# wiz16b8m4ct3_0_WIZ16B8M4CT3 register map
Vendor: Texas Instruments
Registers are 32-bit, read-write, reset 0x0 unless marked. A register's access mark holds for its fields unless they carry their own. Offsets are as the file gives them; [hi:lo] are bit positions; {n}, {i} and the like mark numbered series.

## wiz16b8m4ct3_0_WIZ16B8M4CT3 (part 3 of 12)
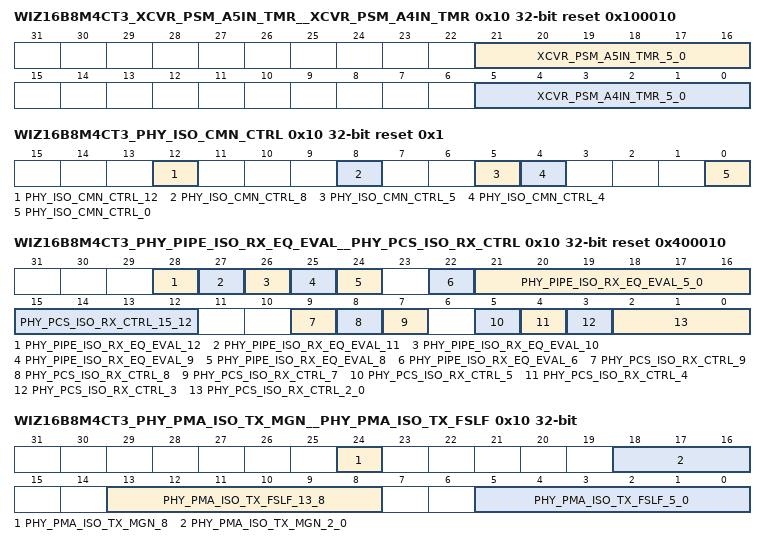
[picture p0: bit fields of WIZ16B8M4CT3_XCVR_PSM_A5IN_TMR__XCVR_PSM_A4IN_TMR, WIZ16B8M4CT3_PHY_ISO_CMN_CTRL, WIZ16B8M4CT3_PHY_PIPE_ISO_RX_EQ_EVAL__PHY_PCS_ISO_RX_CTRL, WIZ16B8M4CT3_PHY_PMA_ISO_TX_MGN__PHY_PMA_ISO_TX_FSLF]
0x10 WIZ16B8M4CT3_XCVR_PSM_A5IN_TMR__XCVR_PSM_A4IN_TMR reset 0x100010
  [21:16] XCVR_PSM_A5IN_TMR_5_0 — A5 in delay state timer value : Value used for the timer when the power state machine is in the A5 in delay state. This timer delay is specified as the number of PSM clocks to count to implement the time required for tpsm_A5_in_del. Note, the smallest value this field is allowed to be is 6'h01. With that said, setting this field to a value smaller than the reset value will likely result in incorrect function.
  [5:0] XCVR_PSM_A4IN_TMR_5_0 — A4 in delay state timer value : Value used for the timer when the power state machine is in the A4 in delay state. This timer delay is specified as the number of PSM clocks to count to implement the time required for tpsm_A4_in_del. Note, the smallest value this field is allowed to be is 6'h01. With that said, setting this field to a value smaller than the reset value will likely result in incorrect function.
0x10 WIZ16B8M4CT3_PHY_ISO_CMN_CTRL access per field reset 0x1
  [12] PHY_ISO_CMN_CTRL_12 ro — Current value of phy_refclk_reqd PHY output.
  [8] PHY_ISO_CMN_CTRL_8 rw — Drives phy_en_refclk PHY input when in PHY macro and PMA isolation mode.
  [5] PHY_ISO_CMN_CTRL_5 rw — Drives phy_pma_suspend_override PHY input when in PHY macro and PMA isolation mode.
  [4] PHY_ISO_CMN_CTRL_4 rw — Drives refclk_rcvr_pwrdn internal PHY signal when in PHY macro and PMA isolation mode (1 = powers down the reference clock receiver). During normal operation, refclk_rcvr_pwrdn is driven from ~abp_preset_n, which powers down the reference clock receiver when the PHY is disabled.
  [0] PHY_ISO_CMN_CTRL_0 rw — Drives phy_reset_n PHY input when in PHY macro and PMA isolation mode.
0x10 WIZ16B8M4CT3_PHY_PIPE_ISO_RX_EQ_EVAL__PHY_PCS_ISO_RX_CTRL access per field reset 0x400010
  [28] PHY_PIPE_ISO_RX_EQ_EVAL_12 rw — Drives pipe_invalid_request for the associated lane when in PHY macro and PMA isolation modes.
  [27] PHY_PIPE_ISO_RX_EQ_EVAL_11 rw — pipe_link_eval_dir_change[5:4] bit reversal enable. When low, no bit reversal. When high, the bit positions for pipe_link_eval_dir_change[5:4] PHY output for the associated lane are reversed.
  [26] PHY_PIPE_ISO_RX_EQ_EVAL_10 rw — pipe_link_eval_dir_change[3:2] bit reversal enable. When low, no bit reversal. When high, the bit positions for pipe_link_eval_dir_change[3:2] PHY output for the associated lane are reversed.
  [25] PHY_PIPE_ISO_RX_EQ_EVAL_9 rw — pipe_link_eval_dir_change[1:0] bit reversal enable. When low, no bit reversal. When high, the bit positions for pipe_link_eval_dir_change[1:0] PHY output for the associated lane are reversed.]
  [24] PHY_PIPE_ISO_RX_EQ_EVAL_8 rw — Drives pipe_rx_eval PHY input for the associated lane when in PHY macro and PMA isolation modes.
  [22] PHY_PIPE_ISO_RX_EQ_EVAL_6 ro — Captures pipe_phy_status for Rx equalization evaluation PHY output for the associated lane (does not include power state change signaling). Set when pipe_phy_status is high and pipe_rx_eq_eval to the PCS is high (i.e. after the isolation MUX). Cleared upon read.
  [21:16] PHY_PIPE_ISO_RX_EQ_EVAL_5_0 ro — pipe_link_eval_dir_change PHY output for the associated lane (prior to bit reversal logic) upon completion of Rx equalization evaluation. Captured upon assertion of Rx equalization eval pipe_phy_status when pipe_rx_eq_eval to the PCS (i.e. after the isolation MUX) is high. Cleared upon read. (Not re-synchronized to apb_pclk)
  [15:12] PHY_PCS_ISO_RX_CTRL_15_12 ro — Current value of pipe_rx_data_k PHY output for the associated lane, when PHY_PCS_ISO_RX_CTRL[5] == 1. Otherwise, 0. (Not re-synchronized to apb_pclk)
  [9] PHY_PCS_ISO_RX_CTRL_9 rw — Drives pipe_rx_eq_training PHY input for the associated lane when in PHY macro and PMA isolation modes.
  [8] PHY_PCS_ISO_RX_CTRL_8 rw — Drives pipe_rx_termination PHY input for the associated lane when in PHY macro and PMA isolation modes.
  [7] PHY_PCS_ISO_RX_CTRL_7 rw — Drives pipe_rx_polarity PHY input for the associated lane when in PHY macro and PMA isolation modes.
  [5] PHY_PCS_ISO_RX_CTRL_5 ro — Current value of pipe_rx_valid PHY output for the associated lane.
  [4] PHY_PCS_ISO_RX_CTRL_4 ro — Current value of pipe_rx_elec_idle PHY output for the associated lane.
  [3] PHY_PCS_ISO_RX_CTRL_3 ro — Current value of pipe_align_detect PHY output for the associated lane.
  [2:0] PHY_PCS_ISO_RX_CTRL_2_0 ro — Current value of pipe_rx_status PHY output for the associated lane. Holds the highest priority pipe_rx_status value seen, since the last register read. Cleared upon read.
0x10 WIZ16B8M4CT3_PHY_PMA_ISO_TX_MGN__PHY_PMA_ISO_TX_FSLF access per field
  [24] PHY_PMA_ISO_TX_MGN_8 rw — Drives tx_low_power_swing_en PMA input for the associated lane when in PMA isolation mode or PHY isolation mode and lane is configured for Raw SerDes mode.
  [18:16] PHY_PMA_ISO_TX_MGN_2_0 rw — Drives tx_vmargin PMA input for the associated lane when in PMA isolation mode or PHY isolation mode and lane is configured for Raw SerDes mode.
  [13:8] PHY_PMA_ISO_TX_FSLF_13_8 ro — Current value of tx_local_fs PMA ouptut for the associated lane. (Not re-synchronized to apb_pclk) Note: In a RTL simulation without UPF, the reset value of this field will be 0x2D.
  [5:0] PHY_PMA_ISO_TX_FSLF_5_0 ro — Current value of tx_local_lf PMA ouptut for the associated lane. (Not re-synchronized to apb_pclk) Note: In a RTL simulation without UPF, the reset value of this field will be 0x0F.
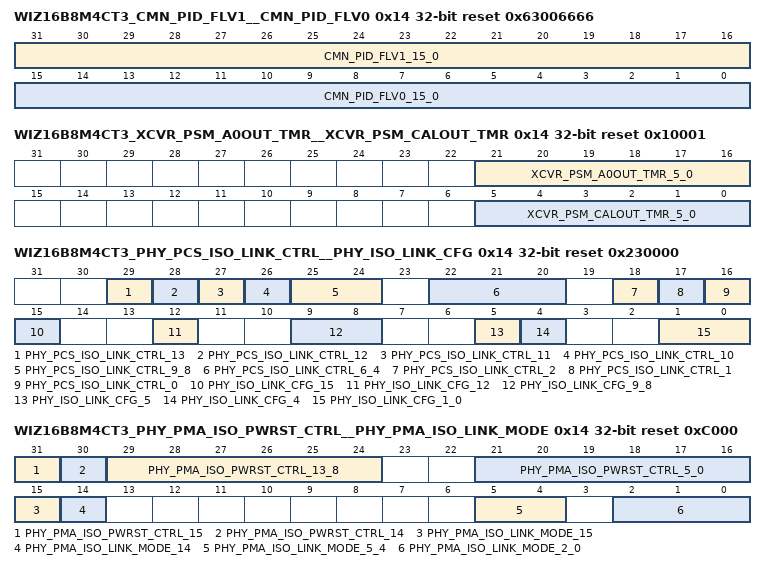
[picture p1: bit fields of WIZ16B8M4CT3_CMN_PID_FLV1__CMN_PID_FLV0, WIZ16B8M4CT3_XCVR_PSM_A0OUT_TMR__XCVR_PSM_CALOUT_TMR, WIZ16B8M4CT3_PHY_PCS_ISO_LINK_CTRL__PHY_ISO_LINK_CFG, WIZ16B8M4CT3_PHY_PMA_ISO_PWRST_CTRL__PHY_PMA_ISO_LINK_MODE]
0x14 WIZ16B8M4CT3_CMN_PID_FLV1__CMN_PID_FLV0 ro reset 0x63006666
  [31:16] CMN_PID_FLV1_15_0 — Product technology flavor : This field contains the ASCII codes that represent the second two characters of the product technology flavor. c
  [15:0] CMN_PID_FLV0_15_0 — Product technology flavor : This field contains the ASCII codes that represent the first two characters of the product technology flavor.
0x14 WIZ16B8M4CT3_XCVR_PSM_A0OUT_TMR__XCVR_PSM_CALOUT_TMR reset 0x10001
  [21:16] XCVR_PSM_A0OUT_TMR_5_0 — A0 out delay state timer value : Value used for the timer when the power state machine is in the A0 out delay state. This timer delay is specified as the number of PSM clocks to count to implement the time required for tpsm_A0_out_del. Note, the smallest value this field is allowed to be is 6'h01. With that said, setting this field to a value smaller than the reset value will likely result in incorrect function.
  [5:0] XCVR_PSM_CALOUT_TMR_5_0 — PSM calibration out delay state timer value : Value used for the timer when the power state machine is in the PSM calibration out delay state. This timer delay is specified as the number of PSM clocks to count to implement the time required for tpsm_lane_cal_out_del. Note, the smallest value this field is allowed to be is 6'h01. With that said, setting this field to a value smaller than the reset value will likely result in incorrect function.
0x14 WIZ16B8M4CT3_PHY_STATE_CHG_TIMEOUT reset 0x30D4
  [15:0] PHY_STATE_CHG_TIMEOUT_15_0 — State change timeout: Bits [19:4] of the state change timeout (bits [3:0] are zero). The timeout is the maximum number of APB clock cycles (abp_pclk) that are allowed for completion of a PHY power state change for the link. If the timeout expires, phy_interrupt_ln_XX for the associated lane is asserted and interrupt status register bit is set. For maximum allowed APB clock frequency, this provides 5.2 msec maximum timeout. Default is set for 1 msec for the maximum APB clock frequency.
0x14 WIZ16B8M4CT3_PHY_PCS_ISO_LINK_CTRL__PHY_ISO_LINK_CFG access per field reset 0x230000
  [29] PHY_PCS_ISO_LINK_CTRL_13 ro — Current value of phy_l*_ack_l1_x PHY output for the associated lane. ()
  [28] PHY_PCS_ISO_LINK_CTRL_12 rw — Drives the phy_l*_ent_l1_x PHY input for the associated lane when in PHY macro and PMA isolation modes. (Link signal - for multi-lane links, master lane used for all lanes in link.)
  [27] PHY_PCS_ISO_LINK_CTRL_11 rw — Drives the phy_l*_rx_elec_idle_det_en PHY input for the associated lane when in PHY macro and PMA isolation modes. (Link signal - for multi-lane links, master lane used for all lanes in link.)
  [26] PHY_PCS_ISO_LINK_CTRL_10 rw — Drives the phy_l*_tx_cmn_mode_en PHY input for the associated lane when in PHY macro and PMA isolation modes. (Link signal - for multi-lane links, master lane used for all lanes in link.)
  [25:24] PHY_PCS_ISO_LINK_CTRL_9_8 rw — Drives the pipe_l*_rate PHY input for the associated lane when in PHY macro and PMA isolation modes. (Link signal - for multi-lane links, master lane used for all lanes in link.)
  [22:20] PHY_PCS_ISO_LINK_CTRL_6_4 rw — Drives the pipe_l*_powerdown PHY input for the associated lane when in PHY macro and PMA isolation modes. (Link signal - for multi-lane links, master lane used for all lanes in link.)
  [18] PHY_PCS_ISO_LINK_CTRL_2 rw — Drives the pipe_l*_tx_det_rx_lpbk PHY input for the associated lane when in PHY macro and PMA isolation modes. (Link signal - for multi-lane links, master lane used for all lanes in link.)
  [17] PHY_PCS_ISO_LINK_CTRL_1 ro — Captures pipe_l*_phy_status (for power state and rate change) PHY output for the associated lane. Set when pipe_phy_status is high and cleared upon read if pipe_phy_status is low. ()
  [16] PHY_PCS_ISO_LINK_CTRL_0 rw — Drives the phy_l*_reset_n PHY input for the associated lane when in PHY macro and PMA isolation modes. (Link signal - for multi-lane links, master lane used for all lanes in link.)
  [15] PHY_ISO_LINK_CFG_15 rw — Drives phy_link_cfg_ln_{nnnn} PHY input when in PHY macro and PMA isolation modes.
  [12] PHY_ISO_LINK_CFG_12 rw — Drives pipe_l{nnnn}_32bit_sel PHY input when in PHY macro and PMA isolation modes.
  [9:8] PHY_ISO_LINK_CFG_9_8 rw — Drives pma_fullrt_div_ln_{nnnn} PHY input when in PHY macro and PMA isolation modes.
  [5] PHY_ISO_LINK_CFG_5 rw — Drives pipe_l{nnnn}_pcie_l1_ss_sel PHY input when in PHY macro and PMA isolation mode.
  [4] PHY_ISO_LINK_CFG_4 rw — Drives pipe_l{nnnn}_eb_mode PHY input when in PHY macro and PMA isolation modes.
  [1:0] PHY_ISO_LINK_CFG_1_0 rw — Drives phy_l{nnnn}_mode PHY input when in PHY macro and PMA isolation modes.
0x14 WIZ16B8M4CT3_PHY_PMA_PLL0_SM_STATE ro reset 0x3000000
  [27:16] PHY_PMA_PLL0_SM_STATE_11_0 — Current value of cmn_pllsm0_state[11:0]. PMA output (Debug only: Not re-synchronized)
0x14 WIZ16B8M4CT3_PHY_PMA_ISO_PWRST_CTRL__PHY_PMA_ISO_LINK_MODE access per field reset 0xC000
  [31] PHY_PMA_ISO_PWRST_CTRL_15 rw — rx_sig_det_en_ext_ln_{nnnn} PMA input when in PMA isolation mode. (Used for PCIe)
  [30] PHY_PMA_ISO_PWRST_CTRL_14 rw — tx_cmn_mode_en_ext_ln_{nnnn} PMA input when in PMA isolation mode. (Used for PCIe)
  [29:24] PHY_PMA_ISO_PWRST_CTRL_13_8 ro — Current value of xcvr_power_state_ack_ln_{nnnn} PMA output.
  [21:16] PHY_PMA_ISO_PWRST_CTRL_5_0 rw — Drives xcvr_power_state_req_ln_{nnnn} PMA input when in PMA isolation mode or PHY isolation mode and lane is configured for Raw SerDes mode..
  [15] PHY_PMA_ISO_LINK_MODE_15 rw — tx_reset_n_ln_{nnnn} PMA input when in PMA isolation mode.
  [14] PHY_PMA_ISO_LINK_MODE_14 rw — rx_reset_n_ln_{nnnn} PMA input when in PMA isolation mode.
  [5:4] PHY_PMA_ISO_LINK_MODE_5_4 rw — Drives xcvr_standard_mode_ln_{nnnn} PMA input when in PMA isolation mode or PHY isolation mode and lane is configured for Raw SerDes mode.
  [2:0] PHY_PMA_ISO_LINK_MODE_2_0 rw — Drives xcvr_data_width_ln_{nnnn} PMA input when in PMA isolation mode or PHY isolation mode and lane is configured for Raw SerDes mode.
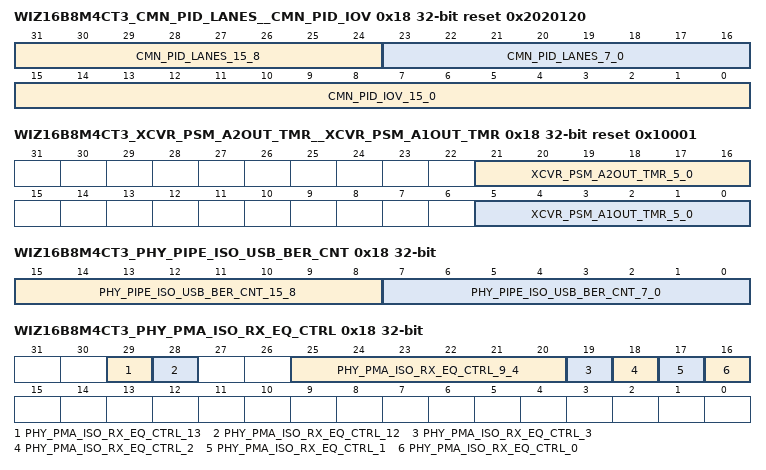
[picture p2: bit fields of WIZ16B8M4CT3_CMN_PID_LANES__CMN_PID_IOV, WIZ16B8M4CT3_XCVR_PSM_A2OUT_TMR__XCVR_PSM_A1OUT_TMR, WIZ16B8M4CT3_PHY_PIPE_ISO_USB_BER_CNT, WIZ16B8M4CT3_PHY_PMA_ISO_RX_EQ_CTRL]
0x18 WIZ16B8M4CT3_CMN_PID_LANES__CMN_PID_IOV ro reset 0x2020120
  [31:24] CMN_PID_LANES_15_8 — Product SerDes lanes left of common : This field contains the binary coded decimal numbers that represent the number of lanes implemented in this SerDes product on the left side of the common module. The following are the possible reset values for this field. 8'h04: 4 lanes on the left side of common. 8'h03: 3 lanes on the left side of common. 8'h02: 2 lanes on the left side of common. 8'h01: 1 lanes on the left side of common. 8'h00: 0 lanes on the left side of common.
  [23:16] CMN_PID_LANES_7_0 — Product SerDes lanes right of common : This field contains the binary coded decimal numbers that represent the number of lanes implemented in this SerDes product on the right side of the common module. The following are the possible reset values for this field. 8'h04: 4 lanes on the right side of common. 8'h03: 3 lanes on the right side of common. 8'h02: 2 lanes on the right side of common. 8'h01: 1 lanes on the right side of common. 8'h00: 0 lanes on the right side of common.
  [15:0] CMN_PID_IOV_15_0 — Product I/O voltage : This field contains the binary coded decimal numbers that represent the product I/O voltage. The most significant byte represents the value to the left of the decimal point, and the least significant byte represents the value to the right of the decimal point. For example, 1.5V is represented as 0x0150.
0x18 WIZ16B8M4CT3_XCVR_PSM_A2OUT_TMR__XCVR_PSM_A1OUT_TMR reset 0x10001
  [21:16] XCVR_PSM_A2OUT_TMR_5_0 — A2 out delay state timer value : Value used for the timer when the power state machine is in the A2 out delay state. This timer delay is specified as the number of PSM clocks to count to implement the time required for tpsm_A2_out_del. Note, the smallest value this field is allowed to be is 6'h01. With that said, setting this field to a value smaller than the reset value will likely result in incorrect function.
  [5:0] XCVR_PSM_A1OUT_TMR_5_0 — A1 out delay state timer value : Value used for the timer when the power state machine is in the A1 out delay state. This timer delay is specified as the number of PSM clocks to count to implement the time required for tpsm_A1_out_del. Note, the smallest value this field is allowed to be is 6'h01. With that said, setting this field to a value smaller than the reset value will likely result in incorrect function.
0x18 WIZ16B8M4CT3_PHY_PIPE_ISO_USB_BER_CNT ro
  [15:8] PHY_PIPE_ISO_USB_BER_CNT_15_8 — Reerved
  [7:0] PHY_PIPE_ISO_USB_BER_CNT_7_0 — Current value of USB 3.1 Gen 1 loopback slave Bit Error Count from the PCS.
0x18 WIZ16B8M4CT3_PHY_PMA_PLL1_SM_STATE ro reset 0x300
  [11:0] PHY_PMA_PLL1_SM_STATE_11_0 — Current value of cmn_pllsm1_state[11:0]. PMA output (Debug only: Not re-synchronized)
0x18 WIZ16B8M4CT3_PHY_PMA_ISO_RX_EQ_CTRL access per field
  [29] PHY_PMA_ISO_RX_EQ_CTRL_13 rw — Drives rx_eq_training_data_valid PMA input for the associated lane when in PMA isolation mode or PHY isolation mode and lane is configured for Raw SerDes mode.
  [28] PHY_PMA_ISO_RX_EQ_CTRL_12 rw — Drives rx_eq_training PMA input for the associated lane when in PMA isolation mode or PHY isolation mode and lane is configured for Raw SerDes mode.
  [25:20] PHY_PMA_ISO_RX_EQ_CTRL_9_4 ro — The value of rx_link_eval_fb_dir_change PMA output for the associated lane upon assertion of rx_eq_eval_status to PMA. Cleared upon read.
  [19] PHY_PMA_ISO_RX_EQ_CTRL_3 ro — The value of rx_eq_eval_complete PMA output for the associated lane upon assertion of rx_eq_eval_status. Cleared upon read.
  [18] PHY_PMA_ISO_RX_EQ_CTRL_2 rw — Drives rx_invalid_request PMA input for the associated lane when in PMA isolation mode.
  [17] PHY_PMA_ISO_RX_EQ_CTRL_1 ro — Current value of rx_eq_eval_status PMA output for the associated lane.
  [16] PHY_PMA_ISO_RX_EQ_CTRL_0 rw — Drives rx_eq_eval PMA input for the associated lane when in PMA isolation mode or PHY isolation mode and lane is configured for Raw SerDes mode.
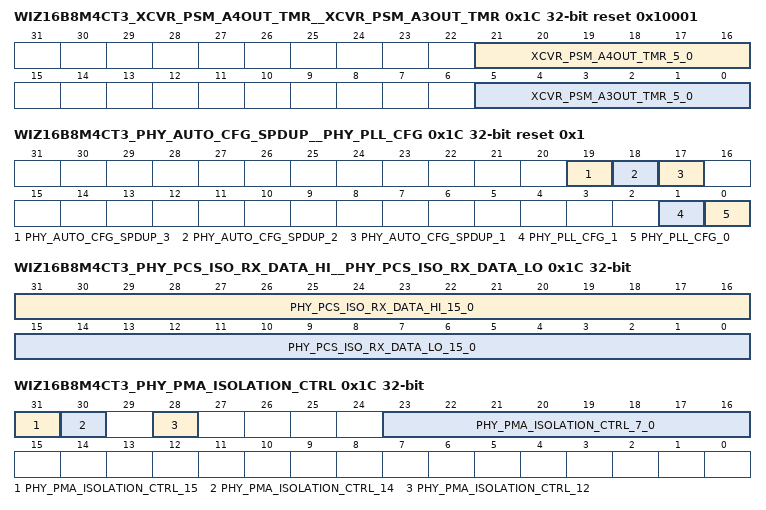
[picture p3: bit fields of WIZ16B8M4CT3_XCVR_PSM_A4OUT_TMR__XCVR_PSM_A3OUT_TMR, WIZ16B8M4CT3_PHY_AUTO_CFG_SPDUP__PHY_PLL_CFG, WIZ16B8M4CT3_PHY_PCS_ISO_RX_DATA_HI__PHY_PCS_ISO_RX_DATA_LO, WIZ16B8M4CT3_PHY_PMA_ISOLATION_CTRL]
0x1C WIZ16B8M4CT3_XCVR_PSM_A4OUT_TMR__XCVR_PSM_A3OUT_TMR reset 0x10001
  [21:16] XCVR_PSM_A4OUT_TMR_5_0 — A4 out delay state timer value : Value used for the timer when the power state machine is in the A4 out delay state. This timer delay is specified as the number of PSM clocks to count to implement the time required for tpsm_A4_out_del. Note, the smallest value this field is allowed to be is 6'h01. With that said, setting this field to a value smaller than the reset value will likely result in incorrect function.
  [5:0] XCVR_PSM_A3OUT_TMR_5_0 — A3 out delay state timer value : Value used for the timer when the power state machine is in the A3 out delay state. This timer delay is specified as the number of PSM clocks to count to implement the time required for tpsm_A3_out_del. Note, the smallest value this field is allowed to be is 6'h01. With that said, setting this field to a value smaller than the reset value will likely result in incorrect function.
0x1C WIZ16B8M4CT3_PHY_AUTO_CFG_SPDUP__PHY_PLL_CFG access per field reset 0x1
  [19] PHY_AUTO_CFG_SPDUP_3 ro — Speedup configuration complete: 1 = PHY speedup configuration is complete, 0 = not complete.
  [18] PHY_AUTO_CFG_SPDUP_2 rw — Speedup configuration stall: 1 = upon completion of PHY speedup configuration, do not release reset to PMA until this bit is cleared, 0 = release reset to PMA upon completion of PHY speedup configuration. Do not set high when [1] = 0.
  [17] PHY_AUTO_CFG_SPDUP_1 rw — Speedup configuration enable: If set to 1 upon de-assertion (high) of phy_reset_n, the PHY will be configured for simulation speedup. Only for use in RTL or gate-level simulations. Not for use in silicon.
  [1] PHY_PLL_CFG_1 rw — PLL configuration: 0 = PHY configured to only use PLL0 / PLL1 disabled. 1 = PHY configured to use both PLL0 and PLL1.
  [0] PHY_PLL_CFG_0 rw — Single link PCIe configuration : 1 = PHY configured such that there is only a single PCIe link (1xN) and all PCIe rates will be driven by PLL0. Any other links are not PCIe and will not use PLL0. 0 = ALl other configurations. This is a static configuration, which can only be changed while phy_reset_n is asserted low.
0x1C WIZ16B8M4CT3_PHY_PCS_ISO_RX_DATA_HI__PHY_PCS_ISO_RX_DATA_LO ro
  [31:16] PHY_PCS_ISO_RX_DATA_HI_15_0 — Current value of pipe_rx_data[31:16] PHY output. (Not re-synchronized to apb_pclk)
  [15:0] PHY_PCS_ISO_RX_DATA_LO_15_0 — Current value of pipe_rx_data[15:0] PHY output. (Not re-synchronized to apb_pclk)
0x1C WIZ16B8M4CT3_PHY_PMA_ISOLATION_CTRL
  [31] PHY_PMA_ISOLATION_CTRL_15 — PHY/PMA isolation enable (isolation_en) - When set, enables isolation (PHY or PMA).
  [30] PHY_PMA_ISOLATION_CTRL_14 — PHY/PMA common isolation enable (cmn_isolation_en) - When in PHY Macro Isolation Mode, the PHY common isolation register(s) are selected. When in PMA Isolation Mode, the PMA common isolation register(s) are selected.
  [28] PHY_PMA_ISOLATION_CTRL_12 — PHY/PMA isolation mode select (isolation_mode_sel) - When isolation_en is set, this bit selects between PHY isolation mode and PMA isolation mode. 0 = PHYMacro isolation mode; 1 = PMA isolation mode.
  [23:16] PHY_PMA_ISOLATION_CTRL_7_0 — PHY/PMA lane isolation enable (ln_isolation_en) - When in PHY Macro Isolation Mode, the selected PHY lane(s) isolation registers are selected. When in PMA Isolation Mode, the selected PMA lane(s) isolation registers are selected.
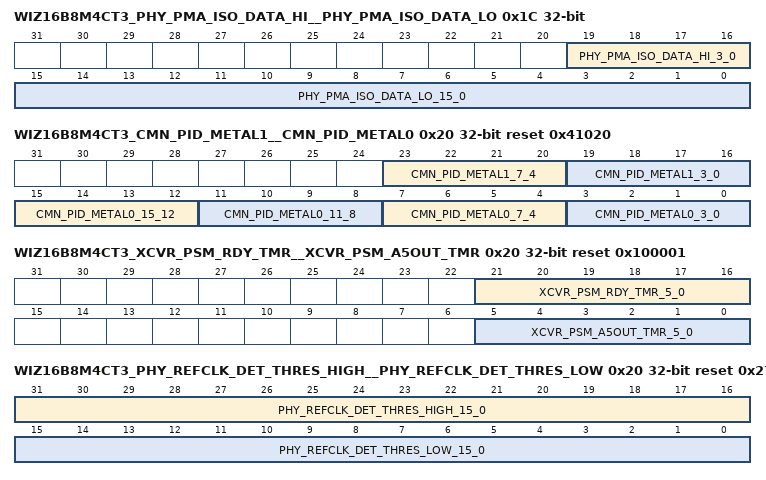
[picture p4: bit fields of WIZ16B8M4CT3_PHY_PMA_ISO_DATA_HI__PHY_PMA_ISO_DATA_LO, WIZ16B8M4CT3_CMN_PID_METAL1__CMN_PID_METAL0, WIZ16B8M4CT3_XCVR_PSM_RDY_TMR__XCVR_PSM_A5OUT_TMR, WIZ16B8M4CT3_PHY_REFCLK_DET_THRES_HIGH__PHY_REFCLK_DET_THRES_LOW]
0x1C WIZ16B8M4CT3_PHY_PMA_ISO_DATA_HI__PHY_PMA_ISO_DATA_LO ro
  [19:16] PHY_PMA_ISO_DATA_HI_3_0 — Current value of rx_rd[19:16] PMA output for the current lane. (Not re-synchronized to apb_pclk). This register can be written and the value will drive tx_td[19:16] for the associated lane when in PMA isolation mode or PHY isolation mode and lane is configured for Raw SerDes mode.
  [15:0] PHY_PMA_ISO_DATA_LO_15_0 — Current value of rx_rd[15:0] PMA output for the current lane. (Not re-synchronized to apb_pclk). This register can be written and the value will drive tx_td[15:0] for the associated lane when in PMA isolation mode or PHY isolation mode and lane is configured for Raw SerDes mode.
0x20 WIZ16B8M4CT3_CMN_PID_METAL1__CMN_PID_METAL0 ro reset 0x41020
  [23:20] CMN_PID_METAL1_7_4 — Product xy metal layers : This field contains the binary coded decimal number that represent the number of xy metal layers used for this product. The following are the possible reset values for this field. 4'h0: For all metal stacks
  [19:16] CMN_PID_METAL1_3_0 — Product xe metal layers : This field contains the binary coded decimal number that represent the number of xe metal layers used for this product. The following are the possible reset values for this field. 4'h3: For the following metal stacks: 4'h4: For all other metal stacks
  [15:12] CMN_PID_METAL0_15_12 — Product xd metal layers : This field contains the binary coded decimal number that represent the number of xd metal layers used for this product. The following are the possible reset values for this field. 4'h2: For all metal stacks
  [11:8] CMN_PID_METAL0_11_8 — Product xc metal layers : This field contains the binary coded decimal number that represent the number of xc metal layers used for this product. The following are the possible reset values for this field. 4'h0: For all metal stacks
  [7:4] CMN_PID_METAL0_7_4 — Product xa metal layers : This field contains the binary coded decimal number that represent the number of xa metal layers used for this product. The following are the possible reset values for this field. 4'h1: For all metal stacks
  [3:0] CMN_PID_METAL0_3_0 — Product x metal layers : This field contains the binary coded decimal number that represent the number of x metal layers used for this product. The following are the possible reset values for this field. 4'h0: For all metal stacks
0x20 WIZ16B8M4CT3_XCVR_PSM_RDY_TMR__XCVR_PSM_A5OUT_TMR reset 0x100001
  [21:16] XCVR_PSM_RDY_TMR_5_0 — Ready delay state timer value : Value used for the timer when the power state machine is in the ready state. This timer delay is specified as the number of PSM clocks to count to implement the minimum time (tpsm_rdy_out_del.) required to remain in this state. Note, the smallest value this field is allowed to be is 6'h01. With that said, setting this field to a value smaller than the reset value will likely result in incorrect function.
  [5:0] XCVR_PSM_A5OUT_TMR_5_0 — A5 out delay state timer value : Value used for the timer when the power state machine is in the A5 out delay state. This timer delay is specified as the number of PSM clocks to count to implement the time required for tpsm_A5_out_del. Note, the smallest value this field is allowed to be is 6'h01. With that said, setting this field to a value smaller than the reset value will likely result in incorrect function.
0x20 WIZ16B8M4CT3_PHY_REFCLK_DET_THRES_HIGH__PHY_REFCLK_DET_THRES_LOW reset 0x274201C2
  [31:16] PHY_REFCLK_DET_THRES_HIGH_15_0 — External Reference Clock Active Detect High Threshold: This is the maximum number of external reference clock cycles which must be counted during the measurement interval to indicate a valid clock detected. The default value is based on 100MHz reference clock frequency and 10 MHZ apb_pclk frequency.
  [15:0] PHY_REFCLK_DET_THRES_LOW_15_0 — External Reference Clock Active Detect Low Threshold: This is the minimum number of external reference clock cycles which must be counted during the measurement interval to indicate a valid clock detected. The default value is based on 100MHz reference clock external frequency and 200 MHz (max) apb_pclk frequency.
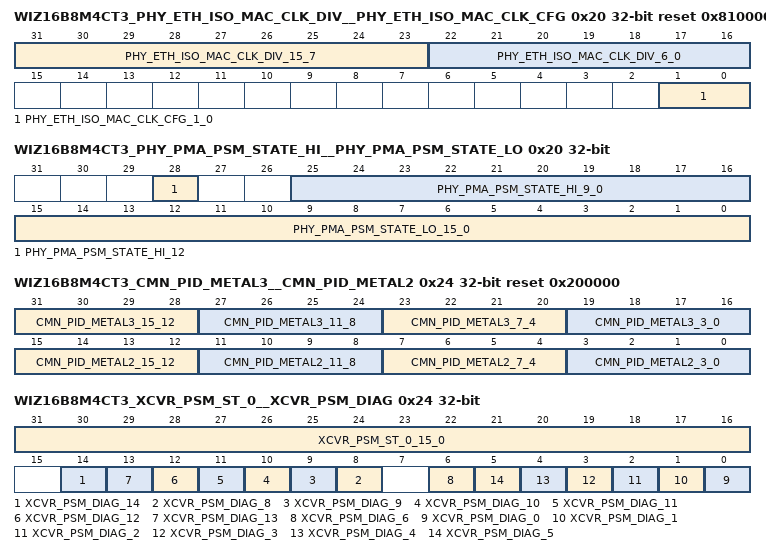
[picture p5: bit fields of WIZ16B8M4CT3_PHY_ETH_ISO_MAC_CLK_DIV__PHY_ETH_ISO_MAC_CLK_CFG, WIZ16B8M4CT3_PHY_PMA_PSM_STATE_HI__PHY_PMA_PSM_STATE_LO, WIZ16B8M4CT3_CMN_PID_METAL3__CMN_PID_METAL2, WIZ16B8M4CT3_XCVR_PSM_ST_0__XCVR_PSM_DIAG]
0x20 WIZ16B8M4CT3_PHY_ETH_ISO_MAC_CLK_DIV__PHY_ETH_ISO_MAC_CLK_CFG reset 0x810000
  [31:23] PHY_ETH_ISO_MAC_CLK_DIV_15_7 — Drives mac_div_sel1 PHY input for the associated lane when in PHY macro and PMA isolation mode.
  [22:16] PHY_ETH_ISO_MAC_CLK_DIV_6_0 — Drives mac_div_sel0 PHY input for the associated lane when in PHY macro and PMA isolation mode.
  [1:0] PHY_ETH_ISO_MAC_CLK_CFG_1_0 — Drives mac_src_sel PHY input for the associated lane when in PHY macro and PMA isolation mode.
0x20 WIZ16B8M4CT3_PHY_PMA_PSM_STATE_HI__PHY_PMA_PSM_STATE_LO ro
  [28] PHY_PMA_PSM_STATE_HI_12 — Current value of xcvr_psm_ready for the associated lane.
  [25:16] PHY_PMA_PSM_STATE_HI_9_0 — Current value of xcvr_psm_state[25:16] for the associated lane - PMA power state machine state. (Not re-synchronized to apb_pclk)
  [15:0] PHY_PMA_PSM_STATE_LO_15_0 — Current value of xcvr_psm_state[15:0] for the associated lane - PMA power state machine state. (Not re-synchronized to apb_pclk)
0x24 WIZ16B8M4CT3_CMN_PID_METAL3__CMN_PID_METAL2 ro reset 0x200000
  [31:28] CMN_PID_METAL3_15_12 — Product yx metal layers : This field contains the binary coded decimal number that represent the number of yx metal layers used for this product. The following are the possible reset values for this field. 4'h0: For all metal stacks
  [27:24] CMN_PID_METAL3_11_8 — Product u metal layers : This field contains the binary coded decimal number that represent the number of u metal layers used for this product. The following are the possible reset values for this field. 4'h0: For all metal stacks
  [23:20] CMN_PID_METAL3_7_4 — Product r metal layers : This field contains the binary coded decimal number that represent the number of r metal layers used for this product. The following are the possible reset values for this field. 4'h0: For the following metal stacks: 4'h2: For all other metal stacks
  [19:16] CMN_PID_METAL3_3_0 — Product z metal layers : This field contains the binary coded decimal number that represent the number of z metal layers used for this product. The following are the possible reset values for this field. 4'h2: For the following metal stacks: 4'h0: For all other metal stacks
  [15:12] CMN_PID_METAL2_15_12 — Product yb metal layers : This field contains the binary coded decimal number that represent the number of yb metal layers used for this product. The following are the possible reset values for this field. 4'h0: For all metal stacks
  [11:8] CMN_PID_METAL2_11_8 — Product yy metal layers : This field contains the binary coded decimal number that represent the number of yy metal layers used for this product. The following are the possible reset values for this field. 4'h0: For all metal stacks
  [7:4] CMN_PID_METAL2_7_4 — Product ya metal layers : This field contains the binary coded decimal number that represent the number of ya metal layers used for this product. The following are the possible reset values for this field. 4'h0: For all metal stacks
  [3:0] CMN_PID_METAL2_3_0 — Product y metal layers : This field contains the binary coded decimal number that represent the number of y metal layers used for this product. The following are the possible reset values for this field. 4'h2: For the following metal stacks: 4'h0: For all other metal stacks
0x24 WIZ16B8M4CT3_XCVR_PSM_ST_0__XCVR_PSM_DIAG access per field
  [31:16] XCVR_PSM_ST_0_15_0 ro — PSM current state[15:0] : Indicates bits 15:0 of the current state of the power state machine.
  [14] XCVR_PSM_DIAG_14 rw — Force calibration exit acknowledge : Setting this bit to 1'b1 forces the psm_cal_exit_ack pin of the power state machine active.
  [n] XCVR_PSM_DIAG_{n} rw (n=8..13) — Force A{n-8} exit acknowledge : Setting this bit to 1'b1 forces the psm_a{n-8}_exit_ack pin of the power state machine active.
  [6] XCVR_PSM_DIAG_6 rw — Force calibration entry acknowledge : Setting this bit to 1'b1 forces the psm_cal_entry_ack pin of the power state machine active.
  [n] XCVR_PSM_DIAG_{n} rw (n=0..5) — Force A{n} entry acknowledge : Setting this bit to 1'b1 forces the psm_a{n}_entry_ack pin of the power state machine active.
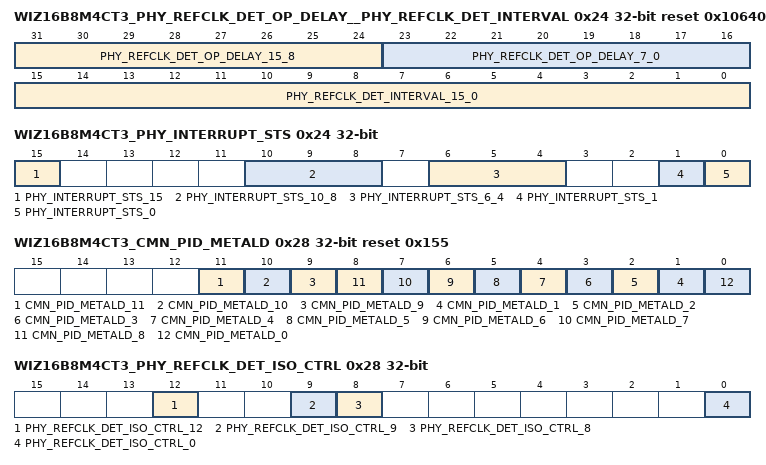
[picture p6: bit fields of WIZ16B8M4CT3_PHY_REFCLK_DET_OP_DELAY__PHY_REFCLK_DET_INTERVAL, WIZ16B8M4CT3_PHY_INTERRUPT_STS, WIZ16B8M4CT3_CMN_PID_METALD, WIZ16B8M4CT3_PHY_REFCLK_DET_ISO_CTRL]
0x24 WIZ16B8M4CT3_PHY_REFCLK_DET_OP_DELAY__PHY_REFCLK_DET_INTERVAL reset 0x106403E8
  [31:24] PHY_REFCLK_DET_OP_DELAY_15_8 — External Reference Clock Active Detect End Delay: This is the number of apb_pclk cycles to wait upon completion of measurement interval before capturing the result (accounts for synchronization delays).
  [23:16] PHY_REFCLK_DET_OP_DELAY_7_0 — External Reference Clock Active Detect Start Delay: This is the number of apb_pclk cycles to wait prior to start of measurement interval (accounts for enable delay of reference clock in PMA).
  [15:0] PHY_REFCLK_DET_INTERVAL_15_0 — External Reference Clock Active Detect Measurement Interval: This is the number of apb_pclk cycles in which to count external reference clock cycles. The default corresponds to 5 us for 200 MHz apb_clk and 100 us for 10 MHz apb_clock.
0x24 WIZ16B8M4CT3_PHY_INTERRUPT_STS access per field
  [15] PHY_INTERRUPT_STS_15 rw — State change monitor enable - 1 = state change monitor enabled, 0 = state change monitor disabled. Note: Only the master lane's state change monitor for a link is enabled. The state change monitor for a slave lane is disabled regardless of the state of this bit.
  [10:8] PHY_INTERRUPT_STS_10_8 ro — Next power state/data rate - Only valid when one of the interrupt status bits is set. Indicates the requested power state or data rate for the state change failure. For PIPE requests, loaded based on the following: For Raw SerDes power state change requests, loaded based on following:
  [6:4] PHY_INTERRUPT_STS_6_4 ro — Current power state/data rate - Only valid when one of the interrupt status bits is set. Indicates the starting power state or data rate for the state change failure. For PIPE requests, loaded based on the following: For Raw SerDes power state change requests, loaded based on following:
  [1] PHY_INTERRUPT_STS_1 rw — Data rate state change interrupt status - Set to 1 upon data rate change timeout. Cleared upon read. Bit is writeable to allow the interrupt to be set manually for test purposes.Only set high by data rate change timeout if bit[0] == 0.
  [0] PHY_INTERRUPT_STS_0 rw — Power state change interrupt status - Set to 1 upon power state change timeout. Cleared upon read. Bit is writeable to allow the interrupt to set manually for test purposes. Only set high by power state change timeout if bit[1] == 0.
0x28 WIZ16B8M4CT3_CMN_PID_METALD ro reset 0x155
  [11] CMN_PID_METALD_11 — Metal 11 direction (when used) : 1'b0 = Vertical, 1'b1 = Horizontal
  [10] CMN_PID_METALD_10 — Metal 10 direction (when used) : 1'b0 = Vertical, 1'b1 = Horizontal. The following are the possible reset values for this field. 1'h0: For the following metal stacks: 1'h1: For the following metal stacks:
  [9] CMN_PID_METALD_9 — Metal 9 direction (when used) : 1'b0 = Vertical, 1'b1 = Horizontal
  [n] CMN_PID_METALD_{n} (n=1..8) — Metal {n} direction : 1'b0 = Vertical, 1'b1 = Horizontal
  [0] CMN_PID_METALD_0 — Metal 0 direction : This layer does not have a direction associated with it.
0x28 WIZ16B8M4CT3_XCVR_PSM_ST_1 ro
  [9:0] XCVR_PSM_ST_1_9_0 — PSM current state[25:16] : Indicates bits 25:16 of the current state of the power state machine.
0x28 WIZ16B8M4CT3_PHY_REFCLK_DET_ISO_CTRL access per field
  [12] PHY_REFCLK_DET_ISO_CTRL_12 ro — Captures the current value of the pma_cmn_ext_refclk_detected_cfg PHY input.
  [9] PHY_REFCLK_DET_ISO_CTRL_9 ro — Current value of pma_cmn_ext_refclk_detected PHY output.
  [8] PHY_REFCLK_DET_ISO_CTRL_8 ro — Current value of pma_cmn_ext_refclk_detected_valid PHY output.
  [0] PHY_REFCLK_DET_ISO_CTRL_0 wo — External Reference Clock Active Detect Start: Write with 1 to initiate an external reference clock active detect operation. Any previous operation must have completed prior to writing with 1.
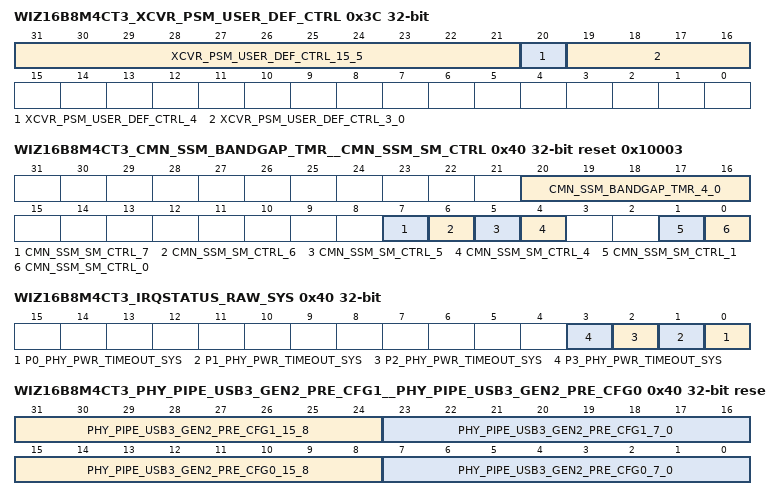
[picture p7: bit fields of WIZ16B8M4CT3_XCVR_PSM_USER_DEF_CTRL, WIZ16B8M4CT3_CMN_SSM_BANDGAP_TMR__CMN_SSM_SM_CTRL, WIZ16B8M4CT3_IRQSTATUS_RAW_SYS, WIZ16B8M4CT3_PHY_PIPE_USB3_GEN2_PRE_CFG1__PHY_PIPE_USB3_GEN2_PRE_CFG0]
0x3C WIZ16B8M4CT3_XCVR_PSM_USER_DEF_CTRL
  [31:21] XCVR_PSM_USER_DEF_CTRL_15_5 — Reserved - spare
  [20] XCVR_PSM_USER_DEF_CTRL_4 — Force PSM gated clock on: Setting this bit to 1'b1 will force the PSM gated clock on, independent of the internal PSM state machine clock gate controls.
  [19:16] XCVR_PSM_USER_DEF_CTRL_3_0 — Reserved - spare
0x40 WIZ16B8M4CT3_CMN_SSM_BANDGAP_TMR__CMN_SSM_SM_CTRL reset 0x10003
  [20:16] CMN_SSM_BANDGAP_TMR_4_0 — Bandgap enable state timer value : Value used for the timer when the startup state machine is in the bandgap enable state. This timer delay is specified as the number of reference clocks to count. This value creates a delay of 40 nSec. Note, when exiting common suspend mode, a total of 1000 nSec is required for the bandgap to be enabled. This total delay is what is ultimately used to determine what the delay needs to be in the bandgap enable state. Of this total time, 960 nSec of this time is accounted for in the suspend recovery state. The remainder is accounted for here.
  [7] CMN_SSM_SM_CTRL_7 — Bandgap enable override enable : When active (1'b1), the bandgap enable override bit in this register will drive the ssmda_bandgap_en pin from the SSM directly.
  [6] CMN_SSM_SM_CTRL_6 — Bandgap enable override : When enabled by the bandgap enable override enable bit in this register, this bit will drive the ssmda_bandgap_en pin from the SSM directly. Note: The bandgap enable hold enable bit in the Startup state machine user defined control register on page 76 must also be set to 1'b0 in order for this register to function correctly.
  [5] CMN_SSM_SM_CTRL_5 — Bias enable override enable : When active (1'b1), the bias enable override bit in this register will drive the ssmda_bias_en pin from the SSM directly.
  [4] CMN_SSM_SM_CTRL_4 — Bias enable override : When enabled by the bias enable override enable bit in this register, this bit will drive the ssmda_bias_en pin from the SSM directly.
  [1] CMN_SSM_SM_CTRL_1 — Skip post bandgap enable re-calibration : When this bit is active (1'b1), the post bandgap enable calibration state will be skipped if it was previously run, unless the macro is disabled or reset.
  [0] CMN_SSM_SM_CTRL_0 — Skip auto re-calibration : When this bit is active (1'b1), the auto calibration state will be skipped if it was previously run, unless the macro is disabled or reset.
0x40 WIZ16B8M4CT3_IRQSTATUS_RAW_SYS access not given
  [n] P{n}_PHY_PWR_TIMEOUT_SYS (n=0..3) — Phy Power Timeout occured for lane {n} error. That is the lane power state took too long to occur.. Write 1 to clear the status after interrupt has been serviced (raw status gets cleared, i.e. even if not enabled). Writing a 0 has no effect. (access R/W1TS)
0x40 WIZ16B8M4CT3_PHY_PIPE_USB3_GEN2_PRE_CFG1__PHY_PIPE_USB3_GEN2_PRE_CFG0 reset 0xA0A
  [31:24] PHY_PIPE_USB3_GEN2_PRE_CFG1_15_8 — USB3 Gen 2 transmit pre-shoot multiplier configuration 3: For a lane configured for USB3 mode at Gen 3 data rate, sets the multiplier configuration for the Tx de-emphasis pre-shoot (C-1) when pipe_lXX_tx_deemphasis[1:0] == 0b11 for the associated lane. Default: 0.
  [23:16] PHY_PIPE_USB3_GEN2_PRE_CFG1_7_0 — USB3 Gen 2 transmit pre-shoot multiplier configuration 2: For a lane configured for USB3 mode at Gen 3 data rate, sets the multiplier configuration for the Tx de-emphasis pre-shoot (C1) when pipe_lXX_tx_deemphasis[1:0] == 0b10 for the associated lane. Default: 0.
  [15:8] PHY_PIPE_USB3_GEN2_PRE_CFG0_15_8 — USB3 Gen 2 transmit pre-shoot multiplier configuration 1: For a lane configured for USB3 mode at Gen 3 data rate, sets the multiplier configuration for the Tx de-emphasis pre-shoot (C-1) when pipe_lXX_tx_deemphasis[1:0] == 0b01 for the associated lane. Default: 5/64.
  [7:0] PHY_PIPE_USB3_GEN2_PRE_CFG0_7_0 — USB3 Gen 2 transmit pre-shoot multiplier configuration 0: For a lane configured for USB3 mode at Gen 3 data rate, sets the multiplier configuration for the Tx de-emphasis pre-shoot (C-1) when pipe_lXX_tx_deemphasis[1:0] == 0b00 for the associated lane. The multiplier is set based on: Default: 5/64.
0x44 WIZ16B8M4CT3_CMN_SSM_BIAS_TMR reset 0x19
  [6:0] CMN_SSM_BIAS_TMR_6_0 — Bias enable state timer value : Value used for the timer when the startup state machine is in the bias enable state. This timer delay is specified as the number of reference clocks to count. This value creates a delay of 1 uSec.
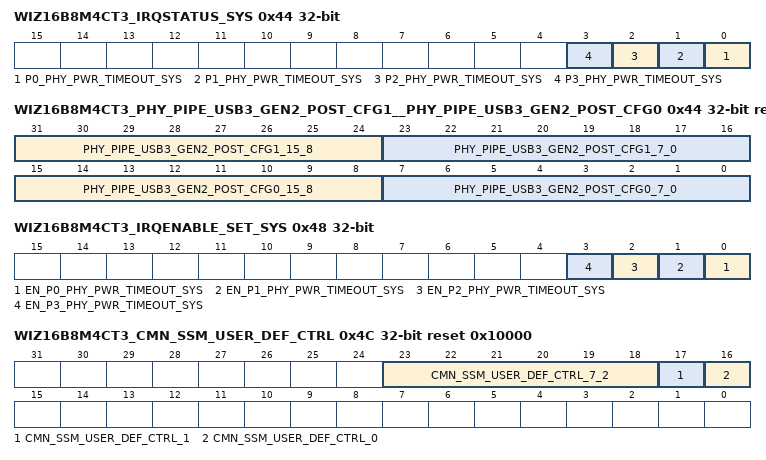
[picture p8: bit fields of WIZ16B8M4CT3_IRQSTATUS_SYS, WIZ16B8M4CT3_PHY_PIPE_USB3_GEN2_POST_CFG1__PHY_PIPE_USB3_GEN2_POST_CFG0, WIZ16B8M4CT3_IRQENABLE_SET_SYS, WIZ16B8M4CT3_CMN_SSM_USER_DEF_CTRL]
0x44 WIZ16B8M4CT3_IRQSTATUS_SYS access not given
  [n] P{n}_PHY_PWR_TIMEOUT_SYS (n=0..3) — Phy Power Timeout occured for lane {n} error. That is the lane power state took too long to occur.. Write 1 to clear the status after interrupt has been serviced (raw status gets cleared, i.e. even if not enabled). Writing a 0 has no effect. (access R/W1TC)
0x44 WIZ16B8M4CT3_PHY_PIPE_USB3_GEN2_POST_CFG1__PHY_PIPE_USB3_GEN2_POST_CFG0 reset 0x101000
  [31:24] PHY_PIPE_USB3_GEN2_POST_CFG1_15_8 — USB3 Gen 2 transmit pre-shoot multiplier configuration 3: For a lane configured for USB3 mode at Gen 3 data rate, sets the multiplier configuration for the Tx de-emphasis (C1) when pipe_lXX_tx_deemphasis[1:0] == 0b11 for the associated lane. Default: 0.
  [23:16] PHY_PIPE_USB3_GEN2_POST_CFG1_7_0 — USB3 Gen 2 transmit pre-shoot multiplier configuration 2: For a lane configured for USB3 mode at Gen 3 data rate, sets the multiplier configuration for the Tx de-emphasis (C1) when pipe_lXX_tx_deemphasis[1:0] == 0b10 for the associated lane. Default: 1/8.
  [15:8] PHY_PIPE_USB3_GEN2_POST_CFG0_15_8 — USB3 Gen 2 transmit pre-shoot multiplier configuration 1: For a lane configured for USB3 mode at Gen 3 data rate, sets the multiplier configuration for the Tx de-emphasis (C1) when pipe_lXX_tx_deemphasis[1:0] == 0b01 for the associated lane. Default: 1/8.
  [7:0] PHY_PIPE_USB3_GEN2_POST_CFG0_7_0 — USB3 Gen 2 transmit pre-shoot multiplier configuration 0: For a lane configured for USB3 mode at Gen 3 data rate, sets the multiplier configuration for the Tx de-emphasis (C1) when pipe_lXX_tx_deemphasis[1:0] == 0b00 for the associated lane. Default: 0.
0x48 WIZ16B8M4CT3_IRQENABLE_SET_SYS access not given
  [n] EN_P{n}_PHY_PWR_TIMEOUT_SYS (n=0..3) — Interrupt Enable set for Phy Power Timeout for lane {n} error. Writing a 1 will enable the interrupt, and set this bit as well as the corresponding Interrupt Enable Set Register. Writing a 0 has no effect. (access R/W1TS)
0x4C WIZ16B8M4CT3_CMN_SSM_USER_DEF_CTRL reset 0x10000
  [23:18] CMN_SSM_USER_DEF_CTRL_7_2 — Reserved - spare
  [17] CMN_SSM_USER_DEF_CTRL_1 — Force SSM gated clock on: Setting this bit to 1'b1 will force the SSM gated clock on, independent of the internal SSM state machine clock gate controls.
  [16] CMN_SSM_USER_DEF_CTRL_0 — Bandgap enable hold enable: This bit enables the bandgap enable hold function, which holds the bandgap enable active in the common suspend state until the signal detect function is switched off.
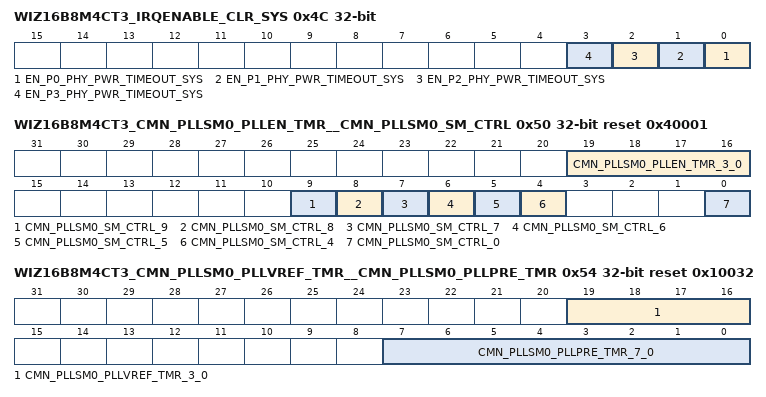
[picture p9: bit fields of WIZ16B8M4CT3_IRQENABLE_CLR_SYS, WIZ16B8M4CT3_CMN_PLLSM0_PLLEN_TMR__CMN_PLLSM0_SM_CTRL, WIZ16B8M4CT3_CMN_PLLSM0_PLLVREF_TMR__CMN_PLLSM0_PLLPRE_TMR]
0x4C WIZ16B8M4CT3_IRQENABLE_CLR_SYS access not given
  [n] EN_P{n}_PHY_PWR_TIMEOUT_SYS (n=0..3) — Interrupt Enable clear for Phy Power Timeout for lane {n} error. Writing a 1 will disable the interrupt, and clear this bit as well as the corresponding Interrupt Enable Set Register. Writing a 0 has no effect. (access R/W1TC)
0x50 WIZ16B8M4CT3_CMN_PLLSM0_PLLEN_TMR__CMN_PLLSM0_SM_CTRL reset 0x40001
  [19:16] CMN_PLLSM0_PLLEN_TMR_3_0 — PLL enable state timer value : Value used for the timer when the startup state machine is in the PLL enable state. This timer delay is specified as the number of reference clocks to count.
  [9] CMN_PLLSM0_SM_CTRL_9 — PLL enable override enable : When active (1'b1), the PLL enable override bit in this register will drive the pllsmda_pll_en pin from the PLLSM directly.
  [8] CMN_PLLSM0_SM_CTRL_8 — PLL enable override : When enabled by the PLL enable override enable bit in this register, this bit will drive the pllsmda_pll_en pin from the PLLSM directly.
  [7] CMN_PLLSM0_SM_CTRL_7 — PLL reset override enable : When active (1'b1), the PLL reset override bit in this register will drive the pllsmda_pll_rst_n pin from the PLLSM directly.
  [6] CMN_PLLSM0_SM_CTRL_6 — PLL reset override : When enabled by the PLL reset override enable bit in this register, this bit will drive the pllsmda_pll_rst_n pin from the PLLSM directly.
  [5] CMN_PLLSM0_SM_CTRL_5 — PLL pre charge override enable : When active (1'b1), the PLL pre charge override bit in this register will drive the pllsmda_pll_pre_charge pin from the PLLSM directly.
  [4] CMN_PLLSM0_SM_CTRL_4 — PLL pre charge override : When enabled by the PLL pre charge override enable bit in this register, this bit will drive the pllsmda_pll_pre_charge pin from the PLLSM directly.
  [0] CMN_PLLSM0_SM_CTRL_0 — Skip PLL re-calibration : When this bit is active (1'b1), the PLL calibration state will be skipped if it was previously run, unless the PLL is disabled or resetting the state machine.
0x54 WIZ16B8M4CT3_CMN_PLLSM0_PLLVREF_TMR__CMN_PLLSM0_PLLPRE_TMR reset 0x10032
  [19:16] CMN_PLLSM0_PLLVREF_TMR_3_0 — PLL VREF delay state timer value : Value used for the timer when the startup state machine is in the PLL VREF delay state. This timer delay is specified as the number of reference clocks to count.
  [7:0] CMN_PLLSM0_PLLPRE_TMR_7_0 — PLL pre-charge state timer value : Value used for the timer when the startup state machine is in the PLL pre-charge state. This timer delay is specified as the number of reference clocks to count. This value creates a delay of 2 uSec.
